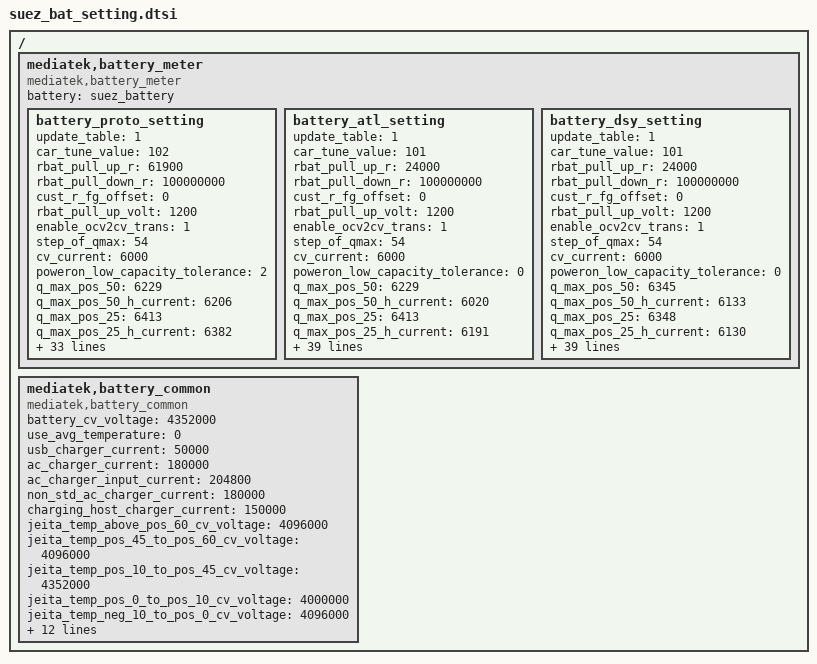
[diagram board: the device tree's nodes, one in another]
/ {
	mediatek,battery_meter {
		compatible = "mediatek,battery_meter";
		battery = "suez_battery";

		battery_proto_setting {
			update_table = <1>;

			car_tune_value = <102>;

			rbat_pull_up_r = <61900>;
			rbat_pull_down_r = <100000000>;
			cust_r_fg_offset = <0>;
			rbat_pull_up_volt = <1200>;

			enable_ocv2cv_trans = <1>;
			step_of_qmax = <54>;
			cv_current = <6000>;

			poweron_low_capacity_tolerance = <2>;

			q_max_pos_50 = <6229>;
			q_max_pos_50_h_current = <6206>;
			q_max_pos_25 = <6413>;
			q_max_pos_25_h_current = <6382>;

			q_max_pos_0 = <6414>;
			q_max_pos_0_h_current = <6263>;
			q_max_neg_10 = <6439>;
			q_max_neg_10_h_current = <5485>;

			batt_temperature_table_num = <19>;
			batt_temperature_table = <
				(-20) 499900
				(-15) 371600
				(-10) 278700
				(-5) 210800
				0 160800
				5 123800
				10 96030
				15 75100
				20 59190
				25 47000
				30 37590
				35 30270
				40 24540
				45 20020
				50 16430
				55 13570
				60 11270
				65 9409
				70 7897
				>;

			r_profile_t0_num = <126>;
			r_profile_t0 = <
				698 4330
				698 4308
				703 4291
				700 4277
				698 4263
				703 4253
				700 4242
				698 4232
				698 4222
				693 4213
				693 4203
				695 4194
				687 4185
				680 4175
				682 4167
				682 4159
				678 4149
				678 4141
				670 4132
				672 4122
				678 4115
				672 4106
				670 4097
				668 4089
				663 4081
				663 4075
				670 4070
				670 4064
				675 4058
				672 4050
				670 4038
				648 4019
				630 4000
				623 3984
				593 3971
				600 3961
				605 3951
				598 3942
				595 3935
				598 3929
				600 3924
				595 3917
				595 3912
				590 3907
				590 3903
				585 3896
				583 3890
				582 3885
				578 3879
				578 3874
				575 3868
				575 3863
				568 3855
				565 3850
				563 3845
				565 3841
				568 3837
				563 3831
				565 3827
				565 3822
				568 3818
				565 3814
				568 3811
				568 3807
				573 3805
				568 3800
				570 3796
				573 3793
				578 3791
				578 3788
				580 3786
				583 3783
				583 3781
				588 3779
				590 3776
				593 3774
				585 3771
				588 3770
				590 3769
				595 3767
				598 3767
				605 3766
				608 3765
				612 3764
				613 3762
				620 3761
				630 3760
				633 3759
				640 3757
				648 3756
				658 3754
				662 3752
				675 3750
				685 3749
				693 3746
				702 3743
				710 3739
				725 3736
				738 3733
				750 3729
				768 3725
				780 3720
				792 3715
				815 3710
				833 3705
				858 3700
				888 3697
				913 3692
				943 3688
				980 3684
				1020 3681
				1070 3677
				1123 3673
				1185 3667
				1250 3657
				1318 3642
				1383 3616
				1448 3576
				1533 3523
				1623 3449
				1485 3394
				1360 3344
				1243 3297
				1128 3251
				1033 3213
				903 3161
				/*
				0 0
				0 0
				0 0
				0 0
				*/
				>;

			r_profile_t1_num = <126>;
			r_profile_t1 = <
				207 4338
				207 4320
				210 4305
				207 4292
				198 4280
				192 4269
				203 4260
				208 4250
				208 4240
				207 4230
				205 4221
				208 4212
				208 4202
				198 4194
				192 4184
				187 4176
				203 4167
				205 4158
				205 4149
				205 4141
				203 4131
				207 4123
				198 4114
				195 4106
				188 4097
				202 4090
				205 4084
				208 4080
				210 4076
				213 4071
				217 4062
				210 4047
				197 4027
				192 4010
				190 3994
				197 3984
				198 3975
				197 3968
				195 3962
				195 3956
				198 3952
				193 3949
				190 3945
				185 3941
				193 3935
				195 3930
				192 3923
				188 3917
				183 3909
				187 3903
				177 3895
				172 3888
				165 3880
				168 3873
				172 3867
				168 3860
				168 3855
				167 3850
				165 3845
				167 3840
				160 3836
				157 3832
				155 3828
				165 3824
				167 3821
				168 3818
				165 3813
				165 3810
				168 3808
				162 3805
				160 3802
				158 3800
				165 3797
				170 3795
				170 3792
				170 3790
				168 3788
				172 3786
				170 3784
				168 3783
				165 3781
				167 3780
				173 3778
				177 3777
				175 3776
				178 3776
				178 3775
				180 3773
				173 3772
				172 3770
				168 3769
				180 3767
				185 3765
				183 3762
				187 3760
				187 3757
				192 3754
				188 3751
				185 3747
				182 3742
				190 3738
				200 3733
				205 3728
				207 3723
				208 3717
				215 3711
				218 3704
				212 3700
				213 3698
				212 3696
				242 3695
				258 3692
				277 3690
				293 3685
				312 3676
				327 3653
				332 3613
				348 3562
				377 3497
				445 3404
				638 3232
				582 3130
				500 3100
				478 3085
				493 3073
				492 3066
				/*
				455 3063
				437 3059
				460 3051
				0 0
				*/
				>;

			r_profile_t1_5_num = <0>;

			r_profile_t2_num = <126>;
			r_profile_t2 = <
				70 4340
				70 4325
				70 4312
				68 4299
				68 4288
				70 4278
				68 4267
				68 4257
				70 4247
				70 4237
				70 4229
				73 4219
				70 4209
				68 4199
				70 4190
				68 4180
				68 4172
				72 4164
				70 4153
				70 4144
				75 4137
				73 4128
				72 4118
				75 4110
				75 4101
				73 4092
				77 4084
				78 4077
				80 4072
				85 4070
				82 4063
				82 4054
				77 4038
				78 4023
				77 4008
				77 3997
				78 3989
				80 3983
				78 3977
				78 3973
				85 3971
				85 3968
				85 3965
				82 3958
				83 3953
				83 3946
				87 3940
				88 3934
				87 3927
				87 3920
				87 3912
				85 3905
				82 3896
				75 3886
				77 3878
				72 3869
				68 3862
				68 3857
				68 3852
				70 3847
				68 3842
				68 3838
				67 3833
				65 3829
				68 3827
				68 3823
				67 3819
				70 3817
				70 3813
				70 3811
				70 3808
				68 3805
				68 3802
				72 3800
				70 3797
				72 3795
				70 3792
				70 3791
				72 3788
				72 3787
				73 3785
				73 3783
				72 3781
				75 3780
				75 3779
				73 3775
				70 3772
				70 3770
				68 3767
				68 3765
				68 3762
				68 3760
				70 3757
				70 3754
				68 3750
				65 3746
				70 3745
				72 3743
				68 3739
				70 3735
				70 3730
				72 3725
				72 3720
				70 3715
				70 3710
				70 3703
				73 3697
				72 3694
				72 3693
				75 3693
				75 3692
				75 3690
				75 3687
				77 3684
				82 3676
				77 3650
				78 3610
				83 3562
				87 3498
				95 3410
				123 3259
				492 3094
				437 3061
				407 3043
				382 3027
				357 3012
				/*
				340 3002
				337 3002
				328 2997
				312 2986
				*/
				>;
			r_profile_t3_num = <126>;
			r_profile_t3 = <
				50 4333
				50 4316
				50 4301
				50 4288
				50 4276
				52 4265
				52 4254
				52 4244
				53 4234
				52 4223
				52 4213
				52 4203
				52 4193
				53 4184
				53 4174
				53 4165
				52 4155
				55 4147
				55 4138
				53 4128
				53 4119
				53 4110
				53 4101
				55 4092
				53 4083
				53 4075
				55 4067
				53 4058
				55 4051
				57 4043
				55 4035
				57 4027
				57 4018
				57 4010
				58 4003
				57 3996
				57 3989
				58 3982
				58 3975
				58 3968
				60 3962
				60 3955
				60 3948
				62 3943
				63 3936
				63 3930
				63 3923
				63 3917
				65 3911
				67 3905
				65 3897
				63 3888
				60 3877
				55 3866
				55 3859
				53 3852
				55 3847
				53 3842
				53 3837
				55 3833
				53 3829
				55 3825
				53 3821
				53 3817
				55 3814
				55 3811
				55 3808
				53 3804
				55 3801
				57 3799
				57 3796
				53 3792
				55 3790
				57 3788
				58 3786
				57 3783
				57 3781
				57 3778
				58 3776
				58 3775
				58 3773
				60 3771
				58 3768
				58 3765
				55 3759
				53 3752
				55 3748
				55 3744
				55 3741
				57 3738
				53 3733
				53 3730
				53 3727
				55 3725
				55 3722
				53 3719
				57 3716
				55 3711
				57 3706
				53 3700
				53 3695
				53 3690
				53 3684
				55 3677
				55 3675
				55 3674
				55 3673
				55 3672
				57 3671
				58 3669
				58 3665
				57 3652
				55 3621
				58 3581
				60 3531
				62 3465
				68 3373
				98 3215
				447 3060
				427 3001
				300 2955
				307 2923
				207 2897
				160 2871
				195 2849
				225 2830
				/*
				158 2820
				163 2806
				187 2792
				210 2780
				*/
				>;

			battery_profile_t0_num = <126>;
			battery_profile_t0 = <
				0 4330
				1 4308
				2 4291
				3 4277
				3 4263
				4 4253
				5 4242
				6 4232
				7 4222
				8 4213
				8 4203
				9 4194
				10 4185
				11 4175
				12 4167
				13 4159
				13 4149
				14 4141
				15 4132
				16 4122
				17 4115
				18 4106
				18 4097
				19 4089
				20 4081
				21 4075
				22 4070
				23 4064
				23 4058
				24 4050
				25 4038
				26 4019
				27 4000
				28 3984
				28 3971
				29 3961
				30 3951
				31 3942
				32 3935
				33 3929
				33 3924
				34 3917
				35 3912
				36 3907
				37 3903
				38 3896
				38 3890
				39 3885
				40 3879
				41 3874
				42 3868
				43 3863
				44 3855
				44 3850
				45 3845
				46 3841
				47 3837
				48 3831
				49 3827
				49 3822
				50 3818
				51 3814
				52 3811
				53 3807
				54 3805
				54 3800
				55 3796
				56 3793
				57 3791
				58 3788
				59 3786
				59 3783
				60 3781
				61 3779
				62 3776
				63 3774
				64 3771
				64 3770
				65 3769
				66 3767
				67 3767
				68 3766
				69 3765
				69 3764
				70 3762
				71 3761
				72 3760
				73 3759
				74 3757
				74 3756
				75 3754
				76 3752
				77 3750
				78 3749
				79 3746
				80 3743
				80 3739
				81 3736
				82 3733
				83 3729
				84 3725
				85 3720
				85 3715
				86 3710
				87 3705
				88 3700
				89 3697
				90 3692
				90 3688
				91 3684
				92 3681
				93 3677
				94 3673
				95 3667
				95 3657
				96 3642
				97 3616
				98 3576
				99 3523
				100 3449
				100 3394
				100 3344
				101 3297
				101 3251
				101 3213
				101 3161
				/*
				0 0
				0 0
				0 0
				0 0
				*/
				>;
			battery_profile_t1_num = <126>;
			battery_profile_t1 = <
				0 4338
				1 4320
				2 4305
				3 4292
				3 4280
				4 4269
				5 4260
				6 4250
				7 4240
				8 4230
				8 4221
				9 4212
				10 4202
				11 4194
				12 4184
				13 4176
				13 4167
				14 4158
				15 4149
				16 4141
				17 4131
				18 4123
				18 4114
				19 4106
				20 4097
				21 4090
				22 4084
				23 4080
				24 4076
				24 4071
				25 4062
				26 4047
				27 4027
				28 4010
				29 3994
				29 3984
				30 3975
				31 3968
				32 3962
				33 3956
				34 3952
				34 3949
				35 3945
				36 3941
				37 3935
				38 3930
				39 3923
				39 3917
				40 3909
				41 3903
				42 3895
				43 3888
				44 3880
				45 3873
				45 3867
				46 3860
				47 3855
				48 3850
				49 3845
				50 3840
				50 3836
				51 3832
				52 3828
				53 3824
				54 3821
				55 3818
				55 3813
				56 3810
				57 3808
				58 3805
				59 3802
				60 3800
				60 3797
				61 3795
				62 3792
				63 3790
				64 3788
				65 3786
				66 3784
				66 3783
				67 3781
				68 3780
				69 3778
				70 3777
				71 3776
				71 3776
				72 3775
				73 3773
				74 3772
				75 3770
				76 3769
				76 3767
				77 3765
				78 3762
				79 3760
				80 3757
				81 3754
				81 3751
				82 3747
				83 3742
				84 3738
				85 3733
				86 3728
				87 3723
				87 3717
				88 3711
				89 3704
				90 3700
				91 3698
				92 3696
				92 3695
				93 3692
				94 3690
				95 3685
				96 3676
				97 3653
				97 3613
				98 3562
				99 3497
				100 3404
				101 3232
				101 3130
				101 3100
				101 3085
				101 3073
				101 3066
				/*
				101 3063
				101 3059
				101 3051
				0 0
				*/
				>;

			battery_profile_t1_5_num = <0>;

			battery_profile_t2_num = <126>;
			battery_profile_t2 = <
				0 4340
				1 4325
				2 4312
				3 4299
				3 4288
				4 4278
				5 4267
				6 4257
				7 4247
				8 4237
				8 4229
				9 4219
				10 4209
				11 4199
				12 4190
				13 4180
				13 4172
				14 4164
				15 4153
				16 4144
				17 4137
				18 4128
				18 4118
				19 4110
				20 4101
				21 4092
				22 4084
				23 4077
				24 4072
				24 4070
				25 4063
				26 4054
				27 4038
				28 4023
				29 4008
				29 3997
				30 3989
				31 3983
				32 3977
				33 3973
				34 3971
				34 3968
				35 3965
				36 3958
				37 3953
				38 3946
				39 3940
				39 3934
				40 3927
				41 3920
				42 3912
				43 3905
				44 3896
				45 3886
				45 3878
				46 3869
				47 3862
				48 3857
				49 3852
				50 3847
				50 3842
				51 3838
				52 3833
				53 3829
				54 3827
				55 3823
				55 3819
				56 3817
				57 3813
				58 3811
				59 3808
				60 3805
				60 3802
				61 3800
				62 3797
				63 3795
				64 3792
				65 3791
				66 3788
				66 3787
				67 3785
				68 3783
				69 3781
				70 3780
				71 3779
				71 3775
				72 3772
				73 3770
				74 3767
				75 3765
				76 3762
				76 3760
				77 3757
				78 3754
				79 3750
				80 3746
				81 3745
				81 3743
				82 3739
				83 3735
				84 3730
				85 3725
				86 3720
				87 3715
				87 3710
				88 3703
				89 3697
				90 3694
				91 3693
				92 3693
				92 3692
				93 3690
				94 3687
				95 3684
				96 3676
				97 3650
				97 3610
				98 3562
				99 3498
				100 3410
				101 3259
				101 3094
				101 3061
				101 3043
				101 3027
				101 3012
				/*
				101 3002
				101 3002
				101 2997
				102 2986
				*/
				>;
			battery_profile_t3_num = <126>;
			battery_profile_t3 = <
				0 4333
				1 4316
				2 4301
				3 4288
				3 4276
				4 4265
				5 4254
				6 4244
				7 4234
				8 4223
				9 4213
				9 4203
				10 4193
				11 4184
				12 4174
				13 4165
				14 4155
				15 4147
				16 4138
				16 4128
				17 4119
				18 4110
				19 4101
				20 4092
				21 4083
				22 4075
				22 4067
				23 4058
				24 4051
				25 4043
				26 4035
				27 4027
				28 4018
				28 4010
				29 4003
				30 3996
				31 3989
				32 3982
				33 3975
				34 3968
				35 3962
				35 3955
				36 3948
				37 3943
				38 3936
				39 3930
				40 3923
				41 3917
				41 3911
				42 3905
				43 3897
				44 3888
				45 3877
				46 3866
				47 3859
				48 3852
				48 3847
				49 3842
				50 3837
				51 3833
				52 3829
				53 3825
				54 3821
				54 3817
				55 3814
				56 3811
				57 3808
				58 3804
				59 3801
				60 3799
				60 3796
				61 3792
				62 3790
				63 3788
				64 3786
				65 3783
				66 3781
				67 3778
				67 3776
				68 3775
				69 3773
				70 3771
				71 3768
				72 3765
				73 3759
				73 3752
				74 3748
				75 3744
				76 3741
				77 3738
				78 3733
				79 3730
				80 3727
				80 3725
				81 3722
				82 3719
				83 3716
				84 3711
				85 3706
				86 3700
				86 3695
				87 3690
				88 3684
				89 3677
				90 3675
				91 3674
				92 3673
				92 3672
				93 3671
				94 3669
				95 3665
				96 3652
				97 3621
				98 3581
				99 3531
				99 3465
				100 3373
				101 3215
				102 3060
				102 3001
				102 2955
				102 2923
				102 2897
				102 2871
				102 2849
				102 2830
				/*
				102 2820
				102 2806
				102 2792
				102 2780
				*/
				>;
		};

		battery_atl_setting {
			update_table = <1>;

			car_tune_value = <101>;

			rbat_pull_up_r = <24000>;
			rbat_pull_down_r = <100000000>;
			cust_r_fg_offset = <0>;
			rbat_pull_up_volt = <1200>;

			enable_ocv2cv_trans = <1>;
			step_of_qmax = <54>;
			cv_current = <6000>;

			poweron_low_capacity_tolerance = <0>;

			q_max_pos_50 = <6229>;
			q_max_pos_50_h_current = <6020>;
			q_max_pos_25 = <6413>;
			q_max_pos_25_h_current = <6191>;
			q_max_pos_10 = <6351>;
			q_max_pos_10_h_current = <6080>;

			q_max_pos_0 = <6414>;
			q_max_pos_0_h_current = <6075>;
			q_max_neg_10 = <6439>;
			q_max_neg_10_h_current = <5320>;

			batt_temperature_table_num = <19>;
			batt_temperature_table = <
				(-20) 499900
				(-15) 371600
				(-10) 278700
				(-5) 210800
				0 160800
				5 123800
				10 96030
				15 75100
				20 59190
				25 47000
				30 37590
				35 30270
				40 24540
				45 20020
				50 16430
				55 13570
				60 11270
				65 9409
				70 7897
				>;
			r_profile_t0_num = <126>;
			r_profile_t0 = <
				698 4330
				698 4308
				703 4291
				700 4277
				698 4263
				703 4253
				700 4242
				698 4232
				698 4222
				693 4213
				693 4203
				695 4194
				687 4185
				680 4175
				682 4167
				682 4159
				678 4149
				678 4141
				670 4132
				672 4122
				678 4115
				672 4106
				670 4097
				668 4089
				663 4081
				663 4075
				670 4070
				670 4064
				675 4058
				672 4050
				670 4038
				648 4019
				630 4000
				623 3984
				593 3971
				600 3961
				605 3951
				598 3942
				595 3935
				598 3929
				600 3924
				595 3917
				595 3912
				590 3907
				590 3903
				585 3896
				583 3890
				582 3885
				578 3879
				578 3874
				575 3868
				575 3863
				568 3855
				565 3850
				563 3845
				565 3841
				568 3837
				563 3831
				565 3827
				565 3822
				568 3818
				565 3814
				568 3811
				568 3807
				573 3805
				568 3800
				570 3796
				573 3793
				578 3791
				578 3788
				580 3786
				583 3783
				583 3781
				588 3779
				590 3776
				593 3774
				585 3771
				588 3770
				590 3769
				595 3767
				598 3767
				605 3766
				608 3765
				612 3764
				613 3762
				620 3761
				630 3760
				633 3759
				640 3757
				648 3756
				658 3754
				662 3752
				675 3750
				685 3749
				693 3746
				702 3743
				710 3739
				725 3736
				738 3733
				750 3729
				768 3725
				780 3720
				792 3715
				815 3710
				833 3705
				858 3700
				888 3697
				913 3692
				943 3688
				980 3684
				1020 3681
				1070 3677
				1123 3673
				1185 3667
				1250 3657
				1318 3642
				1383 3616
				1448 3576
				1533 3523
				1623 3449
				1485 3394
				1360 3344
				1243 3297
				1128 3251
				1033 3213
				903 3161
				>;
			r_profile_t1_num = <126>;
			r_profile_t1 = <
				207 4338
				207 4320
				210 4305
				207 4292
				198 4280
				192 4269
				203 4260
				208 4250
				208 4240
				207 4230
				205 4221
				208 4212
				208 4202
				198 4194
				192 4184
				187 4176
				203 4167
				205 4158
				205 4149
				205 4141
				203 4131
				207 4123
				198 4114
				195 4106
				188 4097
				202 4090
				205 4084
				208 4080
				210 4076
				213 4071
				217 4062
				210 4047
				197 4027
				192 4010
				190 3994
				197 3984
				198 3975
				197 3968
				195 3962
				195 3956
				198 3952
				193 3949
				190 3945
				185 3941
				193 3935
				195 3930
				192 3923
				188 3917
				183 3909
				187 3903
				177 3895
				172 3888
				165 3880
				168 3873
				172 3867
				168 3860
				168 3855
				167 3850
				165 3845
				167 3840
				160 3836
				157 3832
				155 3828
				165 3824
				167 3821
				168 3818
				165 3813
				165 3810
				168 3808
				162 3805
				160 3802
				158 3800
				165 3797
				170 3795
				170 3792
				170 3790
				168 3788
				172 3786
				170 3784
				168 3783
				165 3781
				167 3780
				173 3778
				177 3777
				175 3776
				178 3776
				178 3775
				180 3773
				173 3772
				172 3770
				168 3769
				180 3767
				185 3765
				183 3762
				187 3760
				187 3757
				192 3754
				188 3751
				185 3747
				182 3742
				190 3738
				200 3733
				205 3728
				207 3723
				208 3717
				215 3711
				218 3704
				212 3700
				213 3698
				212 3696
				242 3695
				258 3692
				277 3690
				293 3685
				312 3676
				327 3653
				332 3613
				348 3562
				377 3497
				445 3404
				638 3232
				582 3130
				500 3100
				478 3085
				493 3073
				492 3066
				>;
			r_profile_t1_5_num = <126>;
			r_profile_t1_5 = <
				202 4344
				202 4329
				202 4316
				205 4304
				203 4293
				200 4282
				202 4273
				200 4264
				200 4254
				203 4245
				200 4235
				200 4226
				198 4216
				197 4207
				198 4198
				197 4189
				197 4180
				200 4171
				197 4162
				200 4154
				200 4144
				200 4135
				200 4126
				200 4117
				203 4109
				197 4100
				203 4094
				208 4089
				215 4086
				218 4081
				218 4073
				213 4059
				205 4039
				203 4022
				200 4008
				198 3998
				198 3990
				198 3983
				197 3977
				203 3973
				203 3969
				210 3966
				210 3963
				213 3959
				208 3954
				207 3948
				205 3941
				203 3934
				200 3927
				198 3919
				190 3909
				187 3901
				180 3893
				177 3885
				175 3879
				170 3872
				170 3866
				168 3861
				167 3856
				170 3852
				167 3848
				170 3844
				170 3840
				170 3836
				170 3833
				173 3830
				170 3826
				170 3823
				175 3821
				175 3818
				175 3815
				173 3812
				178 3810
				177 3807
				178 3805
				177 3803
				177 3800
				180 3799
				183 3797
				183 3795
				180 3793
				183 3792
				183 3790
				183 3789
				183 3788
				183 3787
				185 3786
				187 3784
				190 3783
				190 3780
				190 3777
				187 3775
				187 3772
				183 3768
				185 3765
				190 3763
				197 3760
				203 3757
				200 3751
				203 3746
				203 3741
				203 3737
				205 3732
				218 3726
				217 3719
				220 3713
				227 3711
				225 3709
				233 3708
				235 3706
				253 3704
				260 3701
				283 3696
				290 3683
				297 3651
				315 3607
				348 3552
				390 3477
				463 3364
				910 3145
				802 3094
				880 3068
				722 3062
				758 3054
				693 3052
				705 3049
				>;
			r_profile_t2_num = <126>;
			r_profile_t2 = <
				70 4340
				70 4325
				70 4312
				68 4299
				68 4288
				70 4278
				68 4267
				68 4257
				70 4247
				70 4237
				70 4229
				73 4219
				70 4209
				68 4199
				70 4190
				68 4180
				68 4172
				72 4164
				70 4153
				70 4144
				75 4137
				73 4128
				72 4118
				75 4110
				75 4101
				73 4092
				77 4084
				78 4077
				80 4072
				85 4070
				82 4063
				82 4054
				77 4038
				78 4023
				77 4008
				77 3997
				78 3989
				80 3983
				78 3977
				78 3973
				85 3971
				85 3968
				85 3965
				82 3958
				83 3953
				83 3946
				87 3940
				88 3934
				87 3927
				87 3920
				87 3912
				85 3905
				82 3896
				75 3886
				77 3878
				72 3869
				68 3862
				68 3857
				68 3852
				70 3847
				68 3842
				68 3838
				67 3833
				65 3829
				68 3827
				68 3823
				67 3819
				70 3817
				70 3813
				70 3811
				70 3808
				68 3805
				68 3802
				72 3800
				70 3797
				72 3795
				70 3792
				70 3791
				72 3788
				72 3787
				73 3785
				73 3783
				72 3781
				75 3780
				75 3779
				73 3775
				70 3772
				70 3770
				68 3767
				68 3765
				68 3762
				68 3760
				70 3757
				70 3754
				68 3750
				65 3746
				70 3745
				72 3743
				68 3739
				70 3735
				70 3730
				72 3725
				72 3720
				70 3715
				70 3710
				70 3703
				73 3697
				72 3694
				72 3693
				75 3693
				75 3692
				75 3690
				75 3687
				77 3684
				82 3676
				77 3650
				78 3610
				83 3562
				87 3498
				95 3410
				123 3259
				492 3094
				437 3061
				407 3043
				382 3027
				357 3012
				>;
			r_profile_t3_num = <126>;
			r_profile_t3 = <
				50 4333
				50 4316
				50 4301
				50 4288
				50 4276
				52 4265
				52 4254
				52 4244
				53 4234
				52 4223
				52 4213
				52 4203
				52 4193
				53 4184
				53 4174
				53 4165
				52 4155
				55 4147
				55 4138
				53 4128
				53 4119
				53 4110
				53 4101
				55 4092
				53 4083
				53 4075
				55 4067
				53 4058
				55 4051
				57 4043
				55 4035
				57 4027
				57 4018
				57 4010
				58 4003
				57 3996
				57 3989
				58 3982
				58 3975
				58 3968
				60 3962
				60 3955
				60 3948
				62 3943
				63 3936
				63 3930
				63 3923
				63 3917
				65 3911
				67 3905
				65 3897
				63 3888
				60 3877
				55 3866
				55 3859
				53 3852
				55 3847
				53 3842
				53 3837
				55 3833
				53 3829
				55 3825
				53 3821
				53 3817
				55 3814
				55 3811
				55 3808
				53 3804
				55 3801
				57 3799
				57 3796
				53 3792
				55 3790
				57 3788
				58 3786
				57 3783
				57 3781
				57 3778
				58 3776
				58 3775
				58 3773
				60 3771
				58 3768
				58 3765
				55 3759
				53 3752
				55 3748
				55 3744
				55 3741
				57 3738
				53 3733
				53 3730
				53 3727
				55 3725
				55 3722
				53 3719
				57 3716
				55 3711
				57 3706
				53 3700
				53 3695
				53 3690
				53 3684
				55 3677
				55 3675
				55 3674
				55 3673
				55 3672
				57 3671
				58 3669
				58 3665
				57 3652
				55 3621
				58 3581
				60 3531
				62 3465
				68 3373
				98 3215
				447 3060
				427 3001
				300 2955
				307 2923
				207 2897
				160 2871
				195 2849
				225 2830
				>;
			battery_profile_t0_num = <126>;
			battery_profile_t0 = <
				0 4330
				1 4308
				2 4291
				3 4277
				3 4263
				4 4253
				5 4242
				6 4232
				7 4222
				8 4213
				8 4203
				9 4194
				10 4185
				11 4175
				12 4167
				13 4159
				13 4149
				14 4141
				15 4132
				16 4122
				17 4115
				18 4106
				18 4097
				19 4089
				20 4081
				21 4075
				22 4070
				23 4064
				23 4058
				24 4050
				25 4038
				26 4019
				27 4000
				28 3984
				28 3971
				29 3961
				30 3951
				31 3942
				32 3935
				33 3929
				33 3924
				34 3917
				35 3912
				36 3907
				37 3903
				38 3896
				38 3890
				39 3885
				40 3879
				41 3874
				42 3868
				43 3863
				44 3855
				44 3850
				45 3845
				46 3841
				47 3837
				48 3831
				49 3827
				49 3822
				50 3818
				51 3814
				52 3811
				53 3807
				54 3805
				54 3800
				55 3796
				56 3793
				57 3791
				58 3788
				59 3786
				59 3783
				60 3781
				61 3779
				62 3776
				63 3774
				64 3771
				64 3770
				65 3769
				66 3767
				67 3767
				68 3766
				69 3765
				69 3764
				70 3762
				71 3761
				72 3760
				73 3759
				74 3757
				74 3756
				75 3754
				76 3752
				77 3750
				78 3749
				79 3746
				80 3743
				80 3739
				81 3736
				82 3733
				83 3729
				84 3725
				85 3720
				85 3715
				86 3710
				87 3705
				88 3700
				89 3697
				90 3692
				90 3688
				91 3684
				92 3681
				93 3677
				94 3673
				95 3667
				95 3657
				96 3642
				97 3616
				98 3576
				99 3523
				100 3449
				100 3394
				100 3344
				101 3297
				101 3251
				101 3213
				101 3161
				>;
			battery_profile_t1_num = <126>;
			battery_profile_t1 = <
				0 4338
				1 4320
				2 4305
				3 4292
				3 4280
				4 4269
				5 4260
				6 4250
				7 4240
				8 4230
				8 4221
				9 4212
				10 4202
				11 4194
				12 4184
				13 4176
				13 4167
				14 4158
				15 4149
				16 4141
				17 4131
				18 4123
				18 4114
				19 4106
				20 4097
				21 4090
				22 4084
				23 4080
				24 4076
				24 4071
				25 4062
				26 4047
				27 4027
				28 4010
				29 3994
				29 3984
				30 3975
				31 3968
				32 3962
				33 3956
				34 3952
				34 3949
				35 3945
				36 3941
				37 3935
				38 3930
				39 3923
				39 3917
				40 3909
				41 3903
				42 3895
				43 3888
				44 3880
				45 3873
				45 3867
				46 3860
				47 3855
				48 3850
				49 3845
				50 3840
				50 3836
				51 3832
				52 3828
				53 3824
				54 3821
				55 3818
				55 3813
				56 3810
				57 3808
				58 3805
				59 3802
				60 3800
				60 3797
				61 3795
				62 3792
				63 3790
				64 3788
				65 3786
				66 3784
				66 3783
				67 3781
				68 3780
				69 3778
				70 3777
				71 3776
				71 3776
				72 3775
				73 3773
				74 3772
				75 3770
				76 3769
				76 3767
				77 3765
				78 3762
				79 3760
				80 3757
				81 3754
				81 3751
				82 3747
				83 3742
				84 3738
				85 3733
				86 3728
				87 3723
				87 3717
				88 3711
				89 3704
				90 3700
				91 3698
				92 3696
				92 3695
				93 3692
				94 3690
				95 3685
				96 3676
				97 3653
				97 3613
				98 3562
				99 3497
				100 3404
				101 3232
				101 3130
				101 3100
				101 3085
				101 3073
				101 3066
				>;
			battery_profile_t1_5_num = <126>;
			battery_profile_t1_5 = <
				0 4344
				1 4329
				2 4316
				3 4304
				3 4293
				4 4282
				5 4273
				6 4264
				7 4254
				8 4245
				8 4235
				9 4226
				10 4216
				11 4207
				12 4198
				13 4189
				14 4180
				14 4171
				15 4162
				16 4154
				17 4144
				18 4135
				19 4126
				20 4117
				20 4109
				21 4100
				22 4094
				23 4089
				24 4086
				25 4081
				25 4073
				26 4059
				27 4039
				28 4022
				29 4008
				30 3998
				31 3990
				31 3983
				32 3977
				33 3973
				34 3969
				35 3966
				36 3963
				37 3959
				37 3954
				38 3948
				39 3941
				40 3934
				41 3927
				42 3919
				42 3909
				43 3901
				44 3893
				45 3885
				46 3879
				47 3872
				48 3866
				48 3861
				49 3856
				50 3852
				51 3848
				52 3844
				53 3840
				54 3836
				54 3833
				55 3830
				56 3826
				57 3823
				58 3821
				59 3818
				59 3815
				60 3812
				61 3810
				62 3807
				63 3805
				64 3803
				65 3800
				65 3799
				66 3797
				67 3795
				68 3793
				69 3792
				70 3790
				71 3789
				71 3788
				72 3787
				73 3786
				74 3784
				75 3783
				76 3780
				76 3777
				77 3775
				78 3772
				79 3768
				80 3765
				81 3763
				82 3760
				82 3757
				83 3751
				84 3746
				85 3741
				86 3737
				87 3732
				88 3726
				88 3719
				89 3713
				90 3711
				91 3709
				92 3708
				93 3706
				93 3704
				94 3701
				95 3696
				96 3683
				97 3651
				98 3607
				99 3552
				99 3477
				100 3364
				101 3145
				101 3094
				101 3068
				101 3062
				101 3054
				101 3052
				101 3049
				>;
			battery_profile_t2_num = <126>;
			battery_profile_t2 = <
				0 4340
				1 4325
				2 4312
				3 4299
				3 4288
				4 4278
				5 4267
				6 4257
				7 4247
				8 4237
				8 4229
				9 4219
				10 4209
				11 4199
				12 4190
				13 4180
				13 4172
				14 4164
				15 4153
				16 4144
				17 4137
				18 4128
				18 4118
				19 4110
				20 4101
				21 4092
				22 4084
				23 4077
				24 4072
				24 4070
				25 4063
				26 4054
				27 4038
				28 4023
				29 4008
				29 3997
				30 3989
				31 3983
				32 3977
				33 3973
				34 3971
				34 3968
				35 3965
				36 3958
				37 3953
				38 3946
				39 3940
				39 3934
				40 3927
				41 3920
				42 3912
				43 3905
				44 3896
				45 3886
				45 3878
				46 3869
				47 3862
				48 3857
				49 3852
				50 3847
				50 3842
				51 3838
				52 3833
				53 3829
				54 3827
				55 3823
				55 3819
				56 3817
				57 3813
				58 3811
				59 3808
				60 3805
				60 3802
				61 3800
				62 3797
				63 3795
				64 3792
				65 3791
				66 3788
				66 3787
				67 3785
				68 3783
				69 3781
				70 3780
				71 3779
				71 3775
				72 3772
				73 3770
				74 3767
				75 3765
				76 3762
				76 3760
				77 3757
				78 3754
				79 3750
				80 3746
				81 3745
				81 3743
				82 3739
				83 3735
				84 3730
				85 3725
				86 3720
				87 3715
				87 3710
				88 3703
				89 3697
				90 3694
				91 3693
				92 3693
				92 3692
				93 3690
				94 3687
				95 3684
				96 3676
				97 3650
				97 3610
				98 3562
				99 3498
				100 3410
				101 3259
				101 3094
				101 3061
				101 3043
				101 3027
				101 3012
				>;
			battery_profile_t3_num = <126>;
			battery_profile_t3 = <
				0 4333
				1 4316
				2 4301
				3 4288
				3 4276
				4 4265
				5 4254
				6 4244
				7 4234
				8 4223
				9 4213
				9 4203
				10 4193
				11 4184
				12 4174
				13 4165
				14 4155
				15 4147
				16 4138
				16 4128
				17 4119
				18 4110
				19 4101
				20 4092
				21 4083
				22 4075
				22 4067
				23 4058
				24 4051
				25 4043
				26 4035
				27 4027
				28 4018
				28 4010
				29 4003
				30 3996
				31 3989
				32 3982
				33 3975
				34 3968
				35 3962
				35 3955
				36 3948
				37 3943
				38 3936
				39 3930
				40 3923
				41 3917
				41 3911
				42 3905
				43 3897
				44 3888
				45 3877
				46 3866
				47 3859
				48 3852
				48 3847
				49 3842
				50 3837
				51 3833
				52 3829
				53 3825
				54 3821
				54 3817
				55 3814
				56 3811
				57 3808
				58 3804
				59 3801
				60 3799
				60 3796
				61 3792
				62 3790
				63 3788
				64 3786
				65 3783
				66 3781
				67 3778
				67 3776
				68 3775
				69 3773
				70 3771
				71 3768
				72 3765
				73 3759
				73 3752
				74 3748
				75 3744
				76 3741
				77 3738
				78 3733
				79 3730
				80 3727
				80 3725
				81 3722
				82 3719
				83 3716
				84 3711
				85 3706
				86 3700
				86 3695
				87 3690
				88 3684
				89 3677
				90 3675
				91 3674
				92 3673
				92 3672
				93 3671
				94 3669
				95 3665
				96 3652
				97 3621
				98 3581
				99 3531
				99 3465
				100 3373
				101 3215
				102 3060
				102 3001
				102 2955
				102 2923
				102 2897
				102 2871
				102 2849
				102 2830
				>;
		};
		battery_dsy_setting {
			update_table = <1>;

			car_tune_value = <101>;

			rbat_pull_up_r = <24000>;
			rbat_pull_down_r = <100000000>;
			cust_r_fg_offset = <0>;
			rbat_pull_up_volt = <1200>;

			enable_ocv2cv_trans = <1>;
			step_of_qmax = <54>;
			cv_current = <6000>;

			poweron_low_capacity_tolerance = <0>;

			q_max_pos_50 = <6345>;
			q_max_pos_50_h_current = <6133>;
			q_max_pos_25 = <6348>;
			q_max_pos_25_h_current = <6130>;
			q_max_pos_10 = <6210>;
			q_max_pos_10_h_current = <5936>;

			q_max_pos_0 = <6141>;
			q_max_pos_0_h_current = <5568>;
			q_max_neg_10 = <5947>;
			q_max_neg_10_h_current = <5739>;

			batt_temperature_table_num = <19>;
			batt_temperature_table = <
				(-20) 499900
				(-15) 371600
				(-10) 278700
				(-5) 210800
				0 160800
				5 123800
				10 96030
				15 75100
				20 59190
				25 47000
				30 37590
				35 30270
				40 24540
				45 20020
				50 16430
				55 13570
				60 11270
				65 9409
				70 7897
				>;

			r_profile_t0_num = <120>;
			r_profile_t0 = <
				254 4275
				254 4252
				263 4237
				267 4226
				269 4215
				269 4205
				271 4196
				273 4186
				276 4177
				282 4167
				296 4158
				320 4149
				342 4139
				361 4130
				368 4121
				373 4113
				377 4104
				387 4098
				396 4092
				400 4088
				401 4083
				404 4076
				400 4065
				391 4049
				381 4030
				380 4012
				389 3998
				394 3987
				397 3978
				398 3971
				402 3965
				405 3959
				407 3955
				408 3950
				414 3945
				420 3941
				422 3936
				421 3929
				419 3923
				419 3916
				415 3909
				411 3901
				405 3894
				403 3886
				401 3879
				400 3872
				369 3866
				385 3860
				380 3854
				290 3850
				216 3847
				175 3843
				150 3840
				134 3836
				123 3833
				115 3829
				109 3826
				106 3823
				102 3820
				99 3817
				97 3813
				96 3811
				95 3808
				94 3805
				93 3803
				93 3800
				93 3798
				93 3796
				93 3794
				92 3791
				92 3790
				92 3788
				93 3786
				93 3784
				92 3782
				91 3780
				89 3778
				88 3776
				86 3774
				84 3772
				83 3769
				81 3766
				79 3763
				78 3759
				77 3756
				76 3752
				76 3749
				76 3746
				75 3743
				75 3740
				75 3736
				74 3731
				73 3725
				74 3720
				74 3716
				74 3711
				74 3704
				73 3697
				73 3694
				73 3693
				74 3692
				75 3691
				76 3689
				77 3687
				79 3684
				80 3676
				78 3651
				81 3613
				84 3565
				90 3504
				98 3419
				124 3277
				124 3277
				124 3277
				124 3277
				124 3277
				124 3277
				124 3277
				124 3277
				124 3277
				>;

			r_profile_t1_num = <120>;
			r_profile_t1 = <
				230 4287
				230 4267
				240 4253
				244 4241
				251 4230
				252 4220
				254 4210
				255 4201
				256 4192
				259 4183
				261 4175
				262 4166
				263 4157
				266 4148
				267 4139
				269 4130
				270 4121
				270 4113
				269 4105
				269 4098
				261 4091
				197 4088
				239 4084
				248 4079
				249 4070
				245 4055
				240 4036
				232 4018
				211 4003
				257 3990
				265 3982
				267 3975
				268 3969
				270 3963
				272 3960
				274 3956
				278 3952
				280 3949
				280 3945
				280 3940
				280 3935
				277 3929
				277 3923
				274 3915
				272 3908
				269 3899
				265 3890
				263 3882
				260 3874
				258 3867
				256 3861
				255 3855
				253 3850
				255 3845
				255 3841
				218 3836
				255 3832
				257 3829
				258 3825
				257 3822
				259 3819
				259 3816
				260 3813
				262 3810
				263 3807
				265 3805
				266 3802
				263 3800
				266 3798
				269 3796
				270 3794
				270 3792
				271 3790
				274 3789
				276 3788
				277 3787
				277 3786
				278 3785
				282 3784
				285 3784
				285 3783
				290 3781
				292 3780
				295 3779
				299 3777
				300 3775
				304 3773
				306 3770
				309 3768
				311 3765
				317 3761
				309 3756
				280 3755
				334 3750
				342 3745
				351 3740
				358 3735
				368 3730
				373 3725
				385 3719
				393 3712
				402 3706
				417 3704
				431 3702
				446 3700
				463 3698
				484 3695
				507 3692
				533 3685
				559 3670
				575 3639
				611 3594
				661 3536
				729 3457
				822 3335
				822 3335
				822 3335
				822 3335
				822 3335
				822 3335
				>;

			r_profile_t1_5_num = <120>;
			r_profile_t1_5 = <
				123 4309
				123 4292
				126 4279
				128 4268
				131 4258
				132 4248
				133 4238
				132 4229
				133 4219
				132 4210
				134 4201
				135 4192
				137 4183
				139 4174
				140 4165
				141 4156
				140 4147
				141 4138
				140 4129
				143 4120
				143 4112
				146 4103
				147 4095
				148 4088
				151 4084
				153 4080
				156 4076
				156 4069
				154 4056
				148 4037
				148 4019
				147 4005
				147 3994
				145 3985
				146 3978
				145 3972
				146 3967
				148 3964
				151 3961
				154 3958
				155 3955
				155 3951
				153 3945
				154 3939
				150 3933
				152 3925
				149 3917
				147 3907
				142 3897
				138 3888
				135 3879
				131 3872
				129 3865
				129 3860
				129 3855
				127 3850
				130 3846
				130 3841
				131 3837
				129 3834
				129 3830
				129 3826
				131 3823
				130 3820
				132 3817
				133 3814
				133 3811
				134 3808
				133 3806
				132 3803
				133 3801
				133 3798
				133 3796
				135 3794
				136 3791
				137 3790
				136 3788
				136 3786
				136 3784
				137 3783
				138 3781
				138 3780
				141 3779
				141 3778
				141 3776
				140 3774
				140 3772
				139 3770
				140 3767
				140 3764
				141 3761
				143 3758
				144 3755
				144 3752
				143 3749
				143 3744
				144 3739
				144 3734
				144 3729
				148 3725
				151 3719
				152 3711
				151 3705
				154 3702
				156 3701
				160 3699
				164 3698
				168 3697
				179 3694
				182 3686
				134 3681
				186 3653
				207 3612
				223 3561
				250 3495
				285 3400
				407 3225
				407 3225
				407 3225
				407 3225
				>;

			r_profile_t2_num = <120>;
			r_profile_t2 = <
				74 4321
				74 4304
				74 4292
				74 4280
				74 4270
				73 4260
				73 4250
				73 4240
				73 4231
				73 4221
				74 4212
				75 4203
				74 4194
				75 4184
				76 4176
				75 4167
				76 4158
				78 4149
				77 4140
				77 4131
				78 4122
				78 4113
				78 4104
				80 4095
				80 4087
				80 4079
				83 4073
				85 4069
				85 4065
				84 4058
				81 4045
				78 4029
				78 4014
				79 4002
				79 3992
				79 3984
				82 3978
				84 3974
				85 3970
				87 3969
				86 3966
				84 3961
				83 3955
				84 3948
				87 3943
				88 3936
				90 3930
				89 3924
				89 3917
				89 3909
				86 3900
				83 3890
				77 3879
				72 3871
				70 3863
				69 3858
				69 3853
				68 3848
				68 3843
				68 3839
				68 3835
				68 3831
				68 3828
				69 3824
				68 3820
				69 3817
				69 3814
				70 3811
				70 3808
				70 3805
				72 3803
				72 3800
				72 3798
				73 3796
				72 3793
				74 3791
				73 3789
				72 3787
				72 3785
				73 3783
				74 3781
				74 3779
				74 3777
				74 3775
				74 3774
				72 3770
				72 3767
				71 3765
				71 3762
				71 3759
				71 3756
				71 3752
				71 3750
				71 3747
				72 3744
				72 3742
				73 3739
				74 3736
				73 3730
				72 3726
				74 3721
				75 3716
				76 3712
				74 3706
				74 3698
				74 3693
				74 3691
				75 3691
				76 3690
				76 3688
				78 3686
				79 3684
				80 3678
				78 3662
				79 3628
				83 3586
				86 3531
				93 3460
				105 3352
				105 3352
				>;
			r_profile_t3_num = <120>;
			r_profile_t3 = <
				50 4337
				50 4321
				51 4307
				51 4294
				51 4282
				51 4270
				51 4259
				51 4249
				52 4238
				52 4228
				52 4219
				53 4209
				53 4199
				53 4190
				53 4181
				53 4171
				54 4162
				53 4153
				54 4144
				54 4135
				54 4126
				54 4118
				54 4109
				55 4100
				55 4092
				55 4084
				55 4075
				55 4067
				55 4059
				56 4051
				56 4043
				56 4036
				57 4028
				57 4020
				57 4013
				57 4006
				58 3999
				58 3992
				59 3985
				59 3978
				60 3972
				60 3965
				61 3959
				61 3953
				63 3946
				63 3940
				64 3934
				65 3927
				66 3921
				66 3914
				66 3907
				64 3898
				61 3888
				58 3878
				56 3870
				56 3863
				55 3857
				55 3852
				55 3847
				55 3843
				55 3839
				55 3834
				55 3831
				55 3827
				55 3823
				55 3820
				55 3817
				55 3813
				55 3810
				55 3807
				56 3804
				56 3802
				57 3799
				57 3796
				57 3794
				57 3792
				58 3789
				58 3787
				59 3785
				59 3783
				60 3781
				60 3779
				60 3777
				60 3774
				58 3770
				56 3764
				54 3758
				55 3753
				55 3749
				55 3746
				55 3743
				55 3739
				55 3736
				55 3733
				55 3730
				55 3727
				56 3724
				56 3721
				56 3717
				55 3712
				55 3707
				55 3702
				56 3698
				56 3692
				55 3685
				54 3680
				55 3679
				56 3678
				57 3678
				57 3676
				58 3675
				58 3672
				59 3666
				58 3647
				59 3614
				61 3572
				63 3519
				68 3450
				79 3350
				171 3171
				>;

			battery_profile_t0_num = <120>;
			battery_profile_t0 = <
				0 4275
				1 4252
				2 4237
				3 4226
				4 4215
				5 4205
				5 4196
				6 4186
				7 4177
				8 4167
				9 4158
				10 4149
				11 4139
				12 4130
				13 4121
				14 4113
				15 4104
				15 4098
				16 4092
				17 4088
				18 4083
				19 4076
				20 4065
				21 4049
				22 4030
				23 4012
				24 3998
				25 3987
				25 3978
				26 3971
				27 3965
				28 3959
				29 3955
				30 3950
				31 3945
				32 3941
				33 3936
				34 3929
				35 3923
				35 3916
				36 3909
				37 3901
				38 3894
				39 3886
				40 3879
				41 3872
				42 3866
				43 3860
				44 3854
				44 3850
				45 3847
				46 3843
				47 3840
				48 3836
				49 3833
				50 3829
				51 3826
				52 3823
				53 3820
				54 3817
				54 3813
				55 3811
				56 3808
				57 3805
				58 3803
				59 3800
				60 3798
				61 3796
				62 3794
				63 3791
				64 3790
				64 3788
				65 3786
				66 3784
				67 3782
				68 3780
				69 3778
				70 3776
				71 3774
				72 3772
				73 3769
				74 3766
				74 3763
				75 3759
				76 3756
				77 3752
				78 3749
				79 3746
				80 3743
				81 3740
				82 3736
				83 3731
				84 3725
				84 3720
				85 3716
				86 3711
				87 3704
				88 3697
				89 3694
				90 3693
				91 3692
				92 3691
				93 3689
				94 3687
				94 3684
				95 3676
				96 3651
				97 3613
				98 3565
				99 3504
				100 3419
				101 3277
				101 3277
				101 3277
				101 3277
				101 3277
				101 3277
				101 3277
				101 3277
				101 3277
				>;
			battery_profile_t1_num = <120>;
			battery_profile_t1 = <
				0 4287
				1 4267
				2 4253
				3 4241
				4 4230
				4 4220
				5 4210
				6 4201
				7 4192
				8 4183
				9 4175
				10 4166
				11 4157
				11 4148
				12 4139
				13 4130
				14 4121
				15 4113
				16 4105
				17 4098
				18 4091
				18 4088
				19 4084
				20 4079
				21 4070
				22 4055
				23 4036
				24 4018
				25 4003
				26 3990
				26 3982
				27 3975
				28 3969
				29 3963
				30 3960
				31 3956
				32 3952
				33 3949
				33 3945
				34 3940
				35 3935
				36 3929
				37 3923
				38 3915
				39 3908
				40 3899
				40 3890
				41 3882
				42 3874
				43 3867
				44 3861
				45 3855
				46 3850
				47 3845
				47 3841
				48 3836
				49 3832
				50 3829
				51 3825
				52 3822
				53 3819
				54 3816
				55 3813
				55 3810
				56 3807
				57 3805
				58 3802
				59 3800
				60 3798
				61 3796
				62 3794
				62 3792
				63 3790
				64 3789
				65 3788
				66 3787
				67 3786
				68 3785
				69 3784
				69 3784
				70 3783
				71 3781
				72 3780
				73 3779
				74 3777
				75 3775
				76 3773
				77 3770
				77 3768
				78 3765
				79 3761
				80 3756
				81 3755
				82 3750
				83 3745
				84 3740
				84 3735
				85 3730
				86 3725
				87 3719
				88 3712
				89 3706
				90 3704
				91 3702
				91 3700
				92 3698
				93 3695
				94 3692
				95 3685
				96 3670
				97 3639
				98 3594
				98 3536
				99 3457
				100 3335
				100 3335
				100 3335
				100 3335
				100 3335
				100 3335
				>;

			battery_profile_t1_5_num = <120>;
			battery_profile_t1_5 = <
				0 4309
				1 4292
				2 4279
				3 4268
				3 4258
				4 4248
				5 4238
				6 4229
				7 4219
				8 4210
				9 4201
				10 4192
				10 4183
				11 4174
				12 4165
				13 4156
				14 4147
				15 4138
				16 4129
				17 4120
				17 4112
				18 4103
				19 4095
				20 4088
				21 4084
				22 4080
				23 4076
				23 4069
				24 4056
				25 4037
				26 4019
				27 4005
				28 3994
				29 3985
				30 3978
				30 3972
				31 3967
				32 3964
				33 3961
				34 3958
				35 3955
				36 3951
				37 3945
				37 3939
				38 3933
				39 3925
				40 3917
				41 3907
				42 3897
				43 3888
				43 3879
				44 3872
				45 3865
				46 3860
				47 3855
				48 3850
				49 3846
				50 3841
				50 3837
				51 3834
				52 3830
				53 3826
				54 3823
				55 3820
				56 3817
				57 3814
				57 3811
				58 3808
				59 3806
				60 3803
				61 3801
				62 3798
				63 3796
				63 3794
				64 3791
				65 3790
				66 3788
				67 3786
				68 3784
				69 3783
				70 3781
				70 3780
				71 3779
				72 3778
				73 3776
				74 3774
				75 3772
				76 3770
				77 3767
				77 3764
				78 3761
				79 3758
				80 3755
				81 3752
				82 3749
				83 3744
				83 3739
				84 3734
				85 3729
				86 3725
				87 3719
				88 3711
				89 3705
				90 3702
				90 3701
				91 3699
				92 3698
				93 3697
				94 3694
				95 3686
				96 3681
				97 3653
				97 3612
				98 3561
				99 3495
				100 3400
				101 3225
				101 3225
				101 3225
				101 3225
				>;

			battery_profile_t2_num = <120>;
			battery_profile_t2 = <
				0 4321
				1 4304
				2 4292
				3 4280
				3 4270
				4 4260
				5 4250
				6 4240
				7 4231
				8 4221
				9 4212
				9 4203
				10 4194
				11 4184
				12 4176
				13 4167
				14 4158
				14 4149
				15 4140
				16 4131
				17 4122
				18 4113
				19 4104
				20 4095
				20 4087
				21 4079
				22 4073
				23 4069
				24 4065
				25 4058
				26 4045
				26 4029
				27 4014
				28 4002
				29 3992
				30 3984
				31 3978
				31 3974
				32 3970
				33 3969
				34 3966
				35 3961
				36 3955
				37 3948
				37 3943
				38 3936
				39 3930
				40 3924
				41 3917
				42 3909
				43 3900
				43 3890
				44 3879
				45 3871
				46 3863
				47 3858
				48 3853
				48 3848
				49 3843
				50 3839
				51 3835
				52 3831
				53 3828
				54 3824
				54 3820
				55 3817
				56 3814
				57 3811
				58 3808
				59 3805
				60 3803
				60 3800
				61 3798
				62 3796
				63 3793
				64 3791
				65 3789
				66 3787
				66 3785
				67 3783
				68 3781
				69 3779
				70 3777
				71 3775
				71 3774
				72 3770
				73 3767
				74 3765
				75 3762
				76 3759
				77 3756
				77 3752
				78 3750
				79 3747
				80 3744
				81 3742
				82 3739
				83 3736
				83 3730
				84 3726
				85 3721
				86 3716
				87 3712
				88 3706
				88 3698
				89 3693
				90 3691
				91 3691
				92 3690
				93 3688
				94 3686
				94 3684
				95 3678
				96 3662
				97 3628
				98 3586
				99 3531
				100 3460
				100 3352
				100 3352
				>;
			battery_profile_t3_num = <120>;
			battery_profile_t3 = <
				0 4337
				1 4321
				2 4307
				3 4294
				3 4282
				4 4270
				5 4259
				6 4249
				7 4238
				8 4228
				9 4219
				9 4209
				10 4199
				11 4190
				12 4181
				13 4171
				14 4162
				14 4153
				15 4144
				16 4135
				17 4126
				18 4118
				19 4109
				20 4100
				20 4092
				21 4084
				22 4075
				23 4067
				24 4059
				25 4051
				26 4043
				26 4036
				27 4028
				28 4020
				29 4013
				30 4006
				31 3999
				31 3992
				32 3985
				33 3978
				34 3972
				35 3965
				36 3959
				37 3953
				37 3946
				38 3940
				39 3934
				40 3927
				41 3921
				42 3914
				43 3907
				43 3898
				44 3888
				45 3878
				46 3870
				47 3863
				48 3857
				49 3852
				49 3847
				50 3843
				51 3839
				52 3834
				53 3831
				54 3827
				54 3823
				55 3820
				56 3817
				57 3813
				58 3810
				59 3807
				60 3804
				60 3802
				61 3799
				62 3796
				63 3794
				64 3792
				65 3789
				66 3787
				66 3785
				67 3783
				68 3781
				69 3779
				70 3777
				71 3774
				71 3770
				72 3764
				73 3758
				74 3753
				75 3749
				76 3746
				77 3743
				77 3739
				78 3736
				79 3733
				80 3730
				81 3727
				82 3724
				83 3721
				83 3717
				84 3712
				85 3707
				86 3702
				87 3698
				88 3692
				89 3685
				89 3680
				90 3679
				91 3678
				92 3678
				93 3676
				94 3675
				94 3672
				95 3666
				96 3647
				97 3614
				98 3572
				99 3519
				100 3450
				100 3350
				101 3171
				>;
		};
	};
	mediatek,battery_common {
		compatible = "mediatek,battery_common";
		battery_cv_voltage = <4352000>;

		use_avg_temperature = <0>;

		usb_charger_current = <50000>;
		ac_charger_current = <180000>;
		ac_charger_input_current = <204800>;
		non_std_ac_charger_current = <180000>;
		charging_host_charger_current = <150000>;

		/* JEITA parameter */
		jeita_temp_above_pos_60_cv_voltage = <4096000>;
		jeita_temp_pos_45_to_pos_60_cv_voltage = <4096000>;
		jeita_temp_pos_10_to_pos_45_cv_voltage = <4352000>;
		jeita_temp_pos_0_to_pos_10_cv_voltage = <4000000>;
		jeita_temp_neg_10_to_pos_0_cv_voltage = <4096000>;
		jeita_temp_below_neg_10_cv_voltage = <4000000>;
		temp_pos_60_threshold = <60>;
		temp_pos_60_thres_minus_x_degree = <55>;
		temp_pos_45_threshold = <45>;
		temp_pos_45_thres_minus_x_degree = <39>;
		temp_pos_10_threshold = <15>;
		temp_pos_10_thres_plus_x_degree = <16>;
		temp_pos_0_threshold = <0>;
		temp_pos_0_thres_plus_x_degree = <6>;
		temp_neg_10_threshold = <0>;
		temp_neg_10_thres_plus_x_degree = <0>;

		ta_9v_support = <0>;
	};
};
